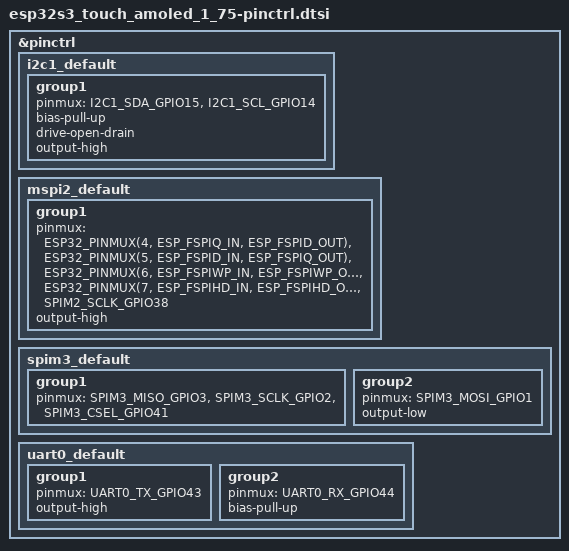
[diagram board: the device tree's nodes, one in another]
/*
 * Copyright (c) 2024 Joel Guittet
 * SPDX-License-Identifier: Apache-2.0
 */

#include <dt-bindings/pinctrl/esp32s3-pinctrl.h>
#include <zephyr/dt-bindings/pinctrl/esp-pinctrl-common.h>
#include <zephyr/dt-bindings/pinctrl/esp32s3-gpio-sigmap.h>

/* #include "esp32s3-qspi-pinctrl.h" */

&pinctrl {

	i2c1_default: i2c1_default {
		group1 {
			pinmux = <I2C1_SDA_GPIO15>, <I2C1_SCL_GPIO14>;
			bias-pull-up;
			drive-open-drain;
			output-high;
		};
	};

	mspi2_default: mspi2_default {
        group1 {
            pinmux = <ESP32_PINMUX(4, ESP_FSPIQ_IN, ESP_FSPID_OUT)>, 	/* D0 */
                     <ESP32_PINMUX(5, ESP_FSPID_IN, ESP_FSPIQ_OUT)>, 	/* D1 */
					 <ESP32_PINMUX(6, ESP_FSPIWP_IN, ESP_FSPIWP_OUT)>, 	/* D2 */
					 <ESP32_PINMUX(7, ESP_FSPIHD_IN, ESP_FSPIHD_OUT)>, 	/* D3 */
					 <SPIM2_SCLK_GPIO38>;							 	/* CLK */
					 /* <SPIM2_CSEL_GPIO12 > CS */

            output-high;
        };
    };

    spim3_default: spim3_default {
		group1 {
			pinmux = <SPIM3_MISO_GPIO3>,
				<SPIM3_SCLK_GPIO2>,
				<SPIM3_CSEL_GPIO41>;
		};
		group2 {
			pinmux = <SPIM3_MOSI_GPIO1>;
			output-low;
		};
	};

	uart0_default: uart0_default {
		group1 {
			pinmux = <UART0_TX_GPIO43>;
			output-high;
		};
		group2 {
			pinmux = <UART0_RX_GPIO44>;
			bias-pull-up;
		};
	};
};
